# STM32H7A3AGI6Q register map
File version: 1.0
Registers are 32-bit, access not given, reset 0x0 unless marked. A register's access mark holds for its fields unless they carry their own. Offsets are from the block's base; [hi:lo] are bit positions; {n}, {i} and the like mark numbered series.

## CRC
Base 0x40023000
0x00 DR
0x04 IDR
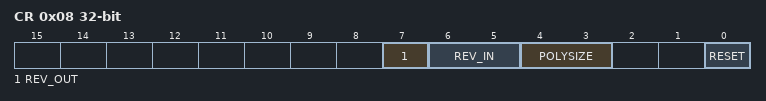
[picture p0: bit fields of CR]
0x08 CR
  [7] REV_OUT, [6:5] REV_IN, [4:3] POLYSIZE, [0] RESET
0x10 INIT
  [31:0] CRC_INIT
0x14 POL

## DCMI
Base 0x48020000
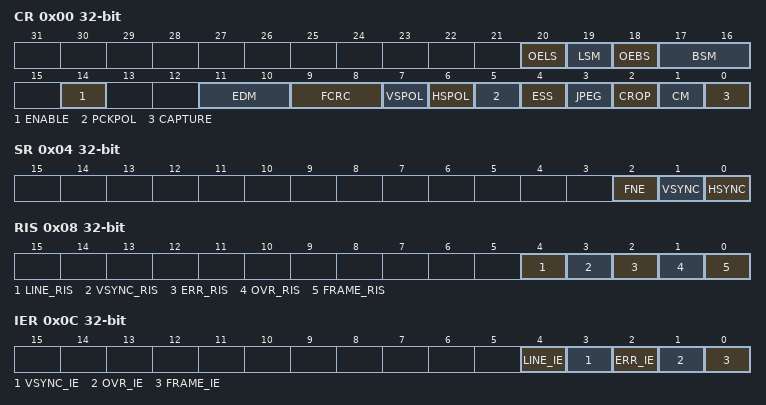
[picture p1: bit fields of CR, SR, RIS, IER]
0x00 CR
  [20] OELS, [19] LSM, [18] OEBS, [17:16] BSM, [14] ENABLE, [11:10] EDM, [9:8] FCRC, [7] VSPOL, [6] HSPOL, [5] PCKPOL, [4] ESS, [3] JPEG, [2] CROP, [1] CM, [0] CAPTURE
0x04 SR
  [2] FNE, [1] VSYNC, [0] HSYNC
0x08 RIS
  [4] LINE_RIS, [3] VSYNC_RIS, [2] ERR_RIS, [1] OVR_RIS, [0] FRAME_RIS
0x0C IER
  [4] LINE_IE, [3] VSYNC_IE, [2] ERR_IE, [1] OVR_IE, [0] FRAME_IE
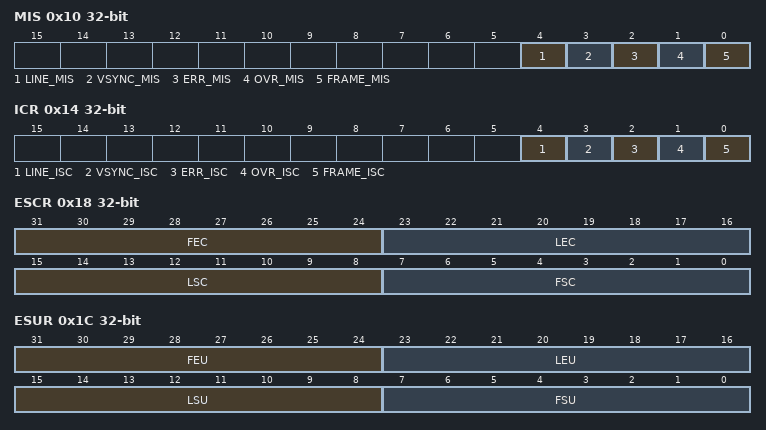
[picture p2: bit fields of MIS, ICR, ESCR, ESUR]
0x10 MIS
  [4] LINE_MIS, [3] VSYNC_MIS, [2] ERR_MIS, [1] OVR_MIS, [0] FRAME_MIS
0x14 ICR
  [4] LINE_ISC, [3] VSYNC_ISC, [2] ERR_ISC, [1] OVR_ISC, [0] FRAME_ISC
0x18 ESCR
  [31:24] FEC, [23:16] LEC, [15:8] LSC, [7:0] FSC
0x1C ESUR
  [31:24] FEU, [23:16] LEU, [15:8] LSU, [7:0] FSU
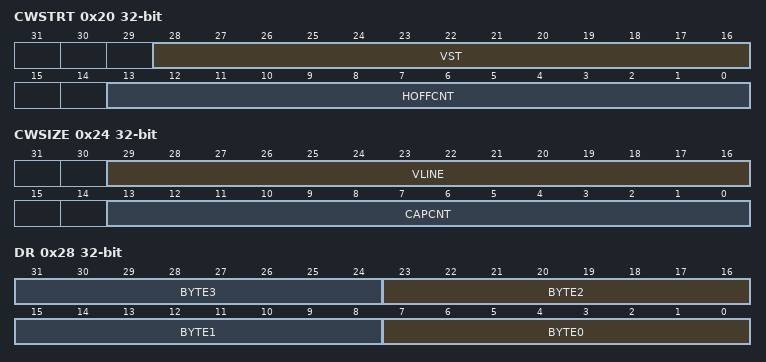
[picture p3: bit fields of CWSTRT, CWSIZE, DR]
0x20 CWSTRT
  [28:16] VST, [13:0] HOFFCNT
0x24 CWSIZE
  [29:16] VLINE, [13:0] CAPCNT
0x28 DR
  [8n+7:8n] BYTE{n} (n=0..3)

## PSSI
Base 0x48020400
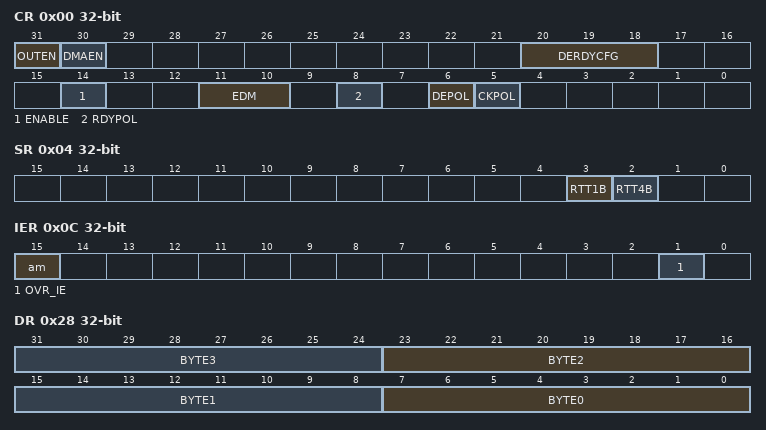
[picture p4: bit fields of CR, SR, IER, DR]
0x00 CR
  [31] OUTEN, [30] DMAEN, [20:18] DERDYCFG, [14] ENABLE, [11:10] EDM, [8] RDYPOL, [6] DEPOL, [5] CKPOL
0x04 SR
  [3] RTT1B, [2] RTT4B
0x08 RIS
  [1] OVR_RIS
0x0C IER
  [15] am, [1] OVR_IE
0x10 MIS
  [1] OVR_MIS
0x14 ICR
  [1] OVR_ISC
0x28 DR
  [8n+7:8n] BYTE{n} (n=0..3)

## HSEM
Base 0x48020800
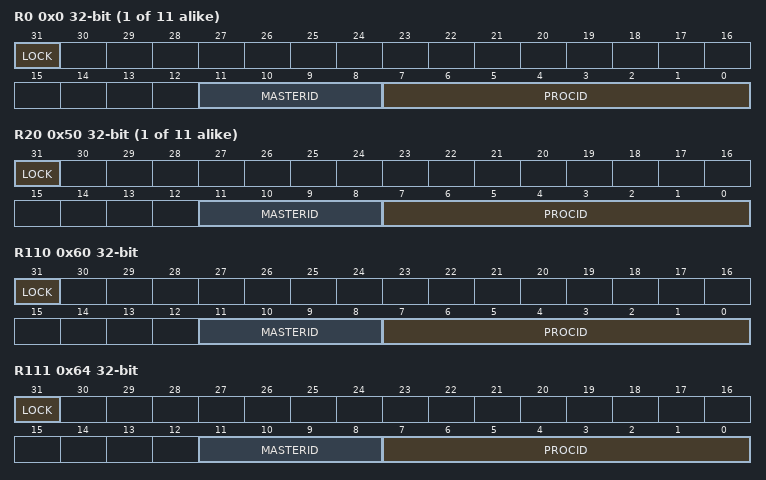
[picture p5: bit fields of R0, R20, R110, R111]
{0x0+4i} R{i} (i=0..10)
  [31] LOCK, [11:8] MASTERID, [7:0] PROCID
{0x0+4i} R{i} (i=20..30)
  [31] LOCK, [11:8] MASTERID, [7:0] PROCID
0x60 R110
  [31] LOCK, [11:8] MASTERID, [7:0] PROCID
0x64 R111
  [31] LOCK, [11:8] MASTERID, [7:0] PROCID
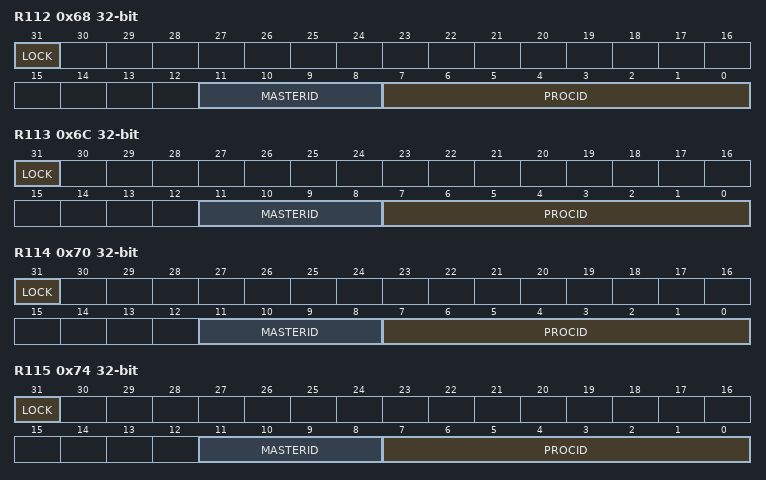
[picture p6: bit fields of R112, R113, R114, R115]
0x68 R112
  [31] LOCK, [11:8] MASTERID, [7:0] PROCID
0x6C R113
  [31] LOCK, [11:8] MASTERID, [7:0] PROCID
0x70 R114
  [31] LOCK, [11:8] MASTERID, [7:0] PROCID
0x74 R115
  [31] LOCK, [11:8] MASTERID, [7:0] PROCID
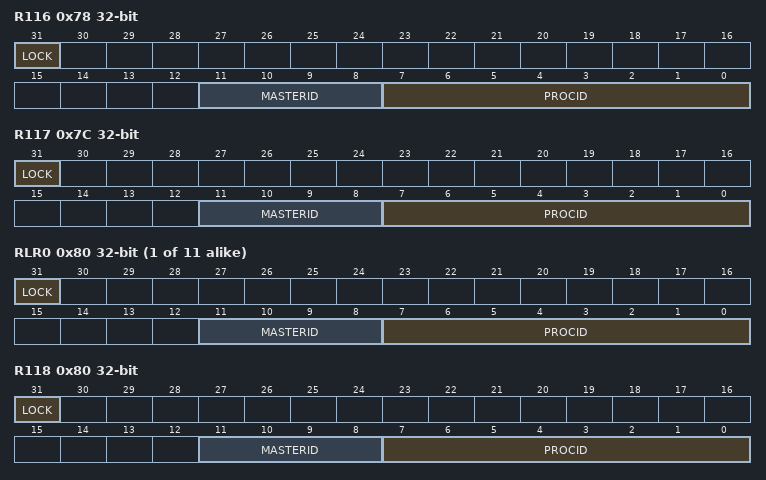
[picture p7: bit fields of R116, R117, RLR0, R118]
0x78 R116
  [31] LOCK, [11:8] MASTERID, [7:0] PROCID
0x7C R117
  [31] LOCK, [11:8] MASTERID, [7:0] PROCID
{0x80+4i} RLR{i} (i=0..10)
  [31] LOCK, [11:8] MASTERID, [7:0] PROCID
0x80 R118
  [31] LOCK, [11:8] MASTERID, [7:0] PROCID
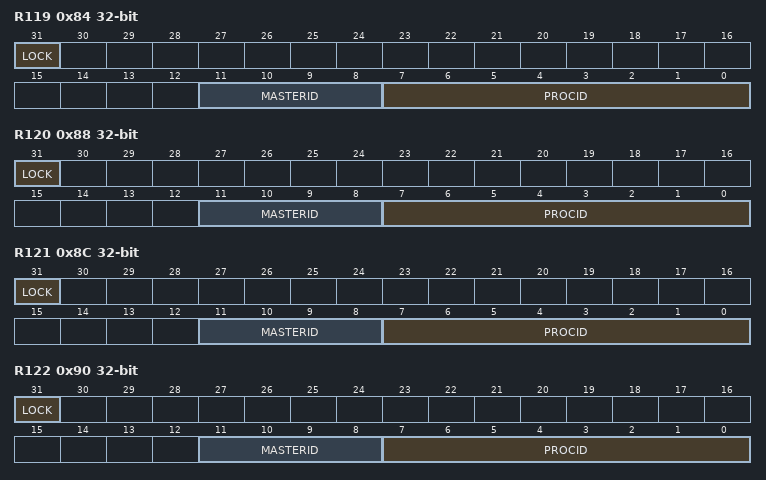
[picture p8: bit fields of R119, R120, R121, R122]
0x84 R119
  [31] LOCK, [11:8] MASTERID, [7:0] PROCID
0x88 R120
  [31] LOCK, [11:8] MASTERID, [7:0] PROCID
0x8C R121
  [31] LOCK, [11:8] MASTERID, [7:0] PROCID
0x90 R122
  [31] LOCK, [11:8] MASTERID, [7:0] PROCID
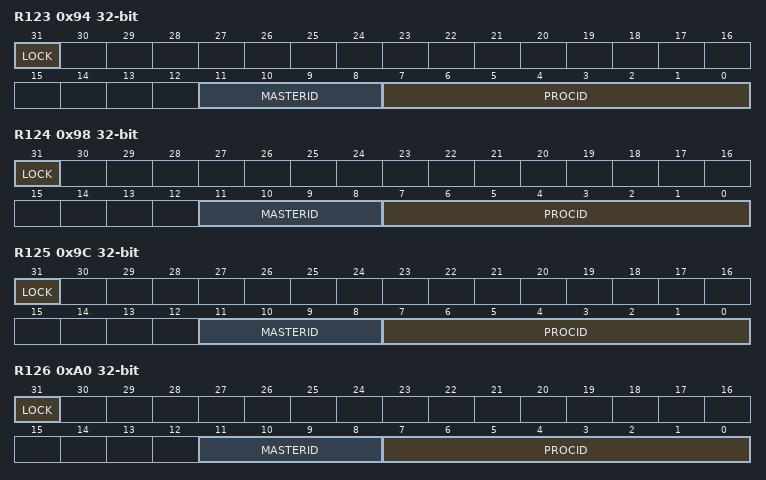
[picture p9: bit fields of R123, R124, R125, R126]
0x94 R123
  [31] LOCK, [11:8] MASTERID, [7:0] PROCID
0x98 R124
  [31] LOCK, [11:8] MASTERID, [7:0] PROCID
0x9C R125
  [31] LOCK, [11:8] MASTERID, [7:0] PROCID
0xA0 R126
  [31] LOCK, [11:8] MASTERID, [7:0] PROCID
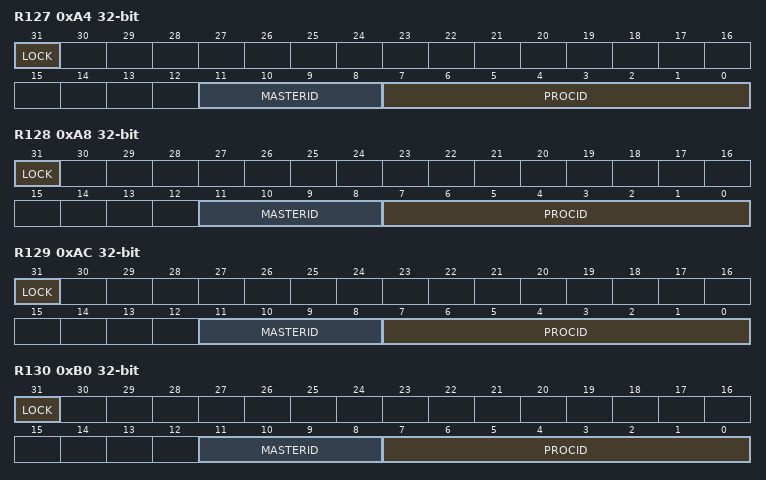
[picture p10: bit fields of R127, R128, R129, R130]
0xA4 R127
  [31] LOCK, [11:8] MASTERID, [7:0] PROCID
0xA8 R128
  [31] LOCK, [11:8] MASTERID, [7:0] PROCID
0xAC R129
  [31] LOCK, [11:8] MASTERID, [7:0] PROCID
0xB0 R130
  [31] LOCK, [11:8] MASTERID, [7:0] PROCID
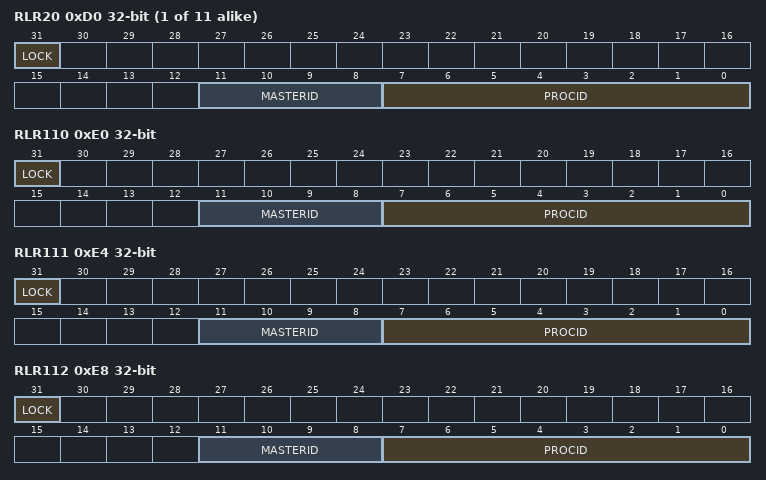
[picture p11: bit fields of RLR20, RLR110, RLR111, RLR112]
{0x80+4i} RLR{i} (i=20..30)
  [31] LOCK, [11:8] MASTERID, [7:0] PROCID
0xE0 RLR110
  [31] LOCK, [11:8] MASTERID, [7:0] PROCID
0xE4 RLR111
  [31] LOCK, [11:8] MASTERID, [7:0] PROCID
0xE8 RLR112
  [31] LOCK, [11:8] MASTERID, [7:0] PROCID
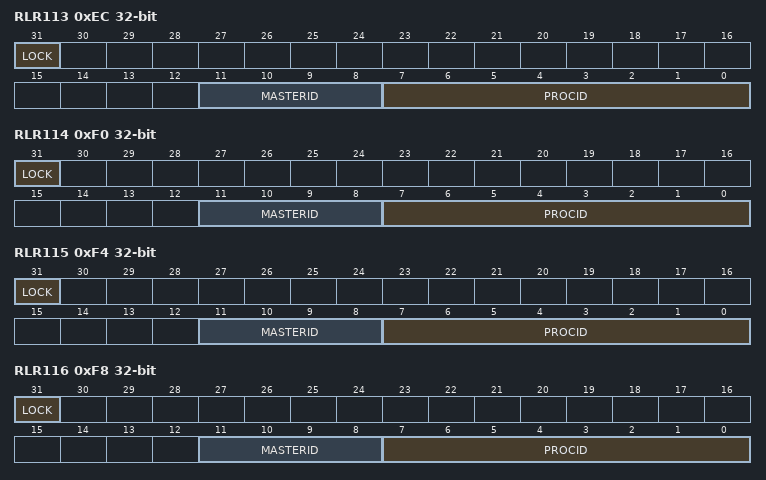
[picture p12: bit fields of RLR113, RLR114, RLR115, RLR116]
0xEC RLR113
  [31] LOCK, [11:8] MASTERID, [7:0] PROCID
0xF0 RLR114
  [31] LOCK, [11:8] MASTERID, [7:0] PROCID
0xF4 RLR115
  [31] LOCK, [11:8] MASTERID, [7:0] PROCID
0xF8 RLR116
  [31] LOCK, [11:8] MASTERID, [7:0] PROCID
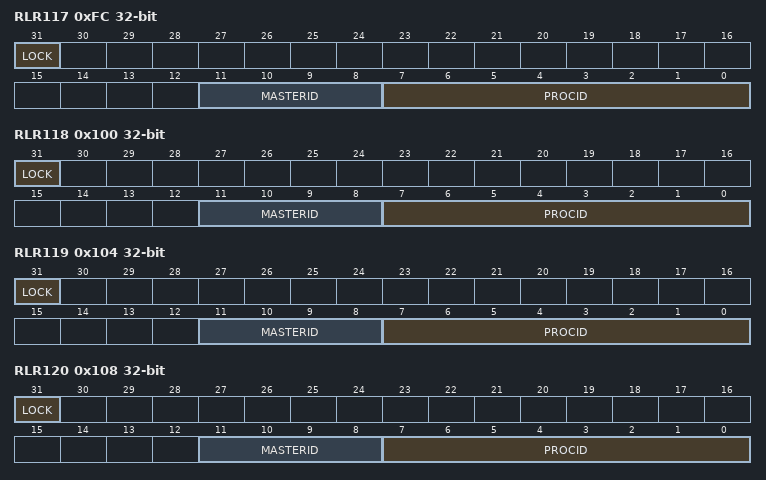
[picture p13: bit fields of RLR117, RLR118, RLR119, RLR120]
0xFC RLR117
  [31] LOCK, [11:8] MASTERID, [7:0] PROCID
0x100 IER
  [15:0] ISE
0x100 RLR118
  [31] LOCK, [11:8] MASTERID, [7:0] PROCID
0x104 ICR
  [15:0] ISC
0x104 RLR119
  [31] LOCK, [11:8] MASTERID, [7:0] PROCID
0x108 ISR
  [15:0] ISF
0x108 RLR120
  [31] LOCK, [11:8] MASTERID, [7:0] PROCID
0x10C MISR
  [15:0] MISF
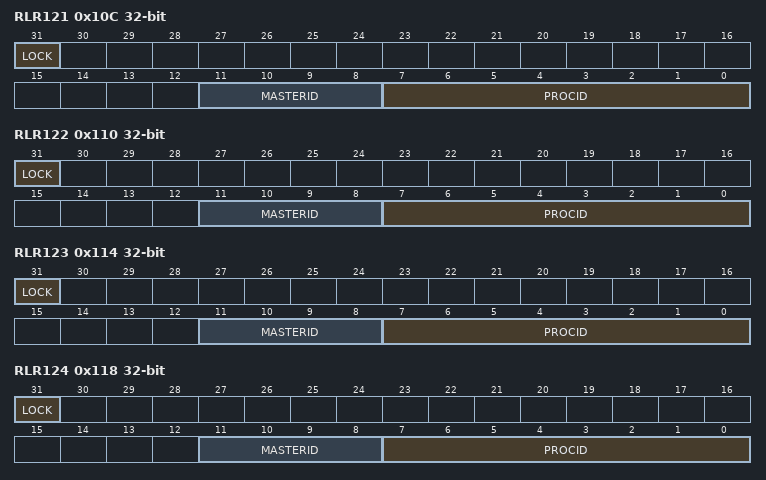
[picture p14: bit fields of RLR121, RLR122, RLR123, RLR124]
0x10C RLR121
  [31] LOCK, [11:8] MASTERID, [7:0] PROCID
0x110 RLR122
  [31] LOCK, [11:8] MASTERID, [7:0] PROCID
0x114 RLR123
  [31] LOCK, [11:8] MASTERID, [7:0] PROCID
0x118 RLR124
  [31] LOCK, [11:8] MASTERID, [7:0] PROCID
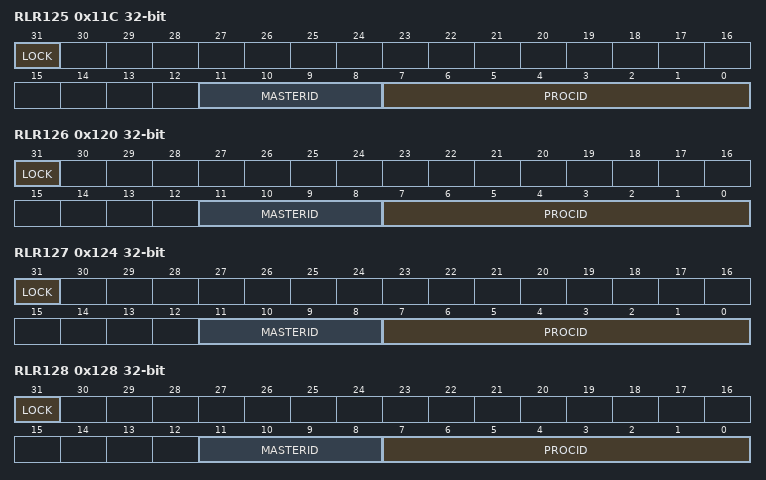
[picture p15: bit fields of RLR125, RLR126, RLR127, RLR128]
0x11C RLR125
  [31] LOCK, [11:8] MASTERID, [7:0] PROCID
0x120 RLR126
  [31] LOCK, [11:8] MASTERID, [7:0] PROCID
0x124 RLR127
  [31] LOCK, [11:8] MASTERID, [7:0] PROCID
0x128 RLR128
  [31] LOCK, [11:8] MASTERID, [7:0] PROCID
0x12C RLR129
  [31] LOCK, [11:8] MASTERID, [7:0] PROCID
0x130 RLR130
  [31] LOCK, [11:8] MASTERID, [7:0] PROCID
0x140 CR
  [31:16] KEY, [11:8] MASTERID
0x144 KEYR
  [31:16] KEY
